# ADC_445 register map
Vendor: Texas Instruments
Peripheral module from a debugger description file (folder msp430).
Registers are 16-bit, read-write, no defined reset value unless marked. A register's access mark holds for its fields unless they carry their own. Offsets are as the file gives them; lines under a group give offsets from that group; [hi:lo] are bit positions; {n}, {i} and the like mark numbered series; 'fields as' and 'values as' point back to an identical list; <NAME> marks a mode.

## ADC
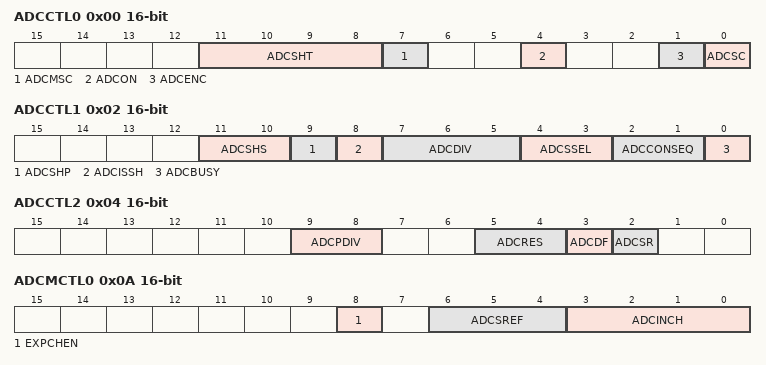
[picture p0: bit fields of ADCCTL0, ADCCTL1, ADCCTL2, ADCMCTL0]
0x00 ADCCTL0 — ADC Control 0
  [11:8] ADCSHT — sample-and-hold time.
    0=4 ADCCLK cycles; 1=8 ADCCLK cycles; 2=16 ADCCLK cycles; 3=32 ADCCLK cycles; 4=64 ADCCLK cycles; 5=96 ADCCLK cycles; 6=128 ADCCLK cycles; 7=192 ADCCLK cycles; 8=256 ADCCLK cycles; 9=384 ADCCLK cycles; 10=512 ADCCLK cycles; 11=768 ADCCLK cycles; {v}=1024 ADCCLK cycles (v=12..15)
  [7] ADCMSC — sample-and-hold time.
    0=The sampling timer requires a rising edge of the SHI signal to trigger each sample-and-convert; 1=The incidence of a positive(or for devices first rising edge of the) SHI signal triggers the sampling timer, but further sample-and-conversions are performed automatically as soon as the prior conversion is completed
  [4] ADCON
    0=ADC off; 1=ADC on
  [1] ADCENC — enable conversion
    0=ADC disabled; 1=ADC enabled
  [0] ADCSC — start conversion
    0=No sample-and-conversion-start; 1=Start sample-and-conversion
0x02 ADCCTL1 access per field — ADC Control 1
  [11:10] ADCSHS rw — sample-and-hold source select
    0=ADCSC bit; 1=see the device-specific data sheet for source; 2=see the device-specific data sheet for source; 3=see the device-specific data sheet for source
  [9] ADCSHP rw — sample-and-hold pulse-mode select
    0=SAMPCON signal is sourced from the sample-input signal; 1=SAMPCON signal is sourced from the sampling timer
  [8] ADCISSH rw — invert signal sample-and-hold
    0=The sample-input signal is not inverted; 1=The sample-input signal is inverted
  [7:5] ADCDIV rw — clock divider
    {v}=/{v+1} (v=0..7)
  [4:3] ADCSSEL rw — clock source select
    0=ADCOSC (MODOSC); 1=ACLK; 2=MCLK; 3=SMCLK
  [2:1] ADCCONSEQ rw — conversion sequence mode select
    0=Single-channel, single-conversion; 1=Sequence-of-channels; 2=Repeat-single-channel; 3=Repeat-sequence-of-channels
  [0] ADCBUSY ro
    0=No operation is active; 1=A sequence, sample, or conversion is active
0x04 ADCCTL2 — ADC Control 2
  [9:8] ADCPDIV — ADC predivider. This bit predivides the selected ADC clock source before it gets divided again using ADCDIVx.
    0=Predivide by 1; 1=Predivide by 4; 2=Predivide by 64
  [5:4] ADCRES — resolution
    0=8 bit; 1=10 bit; 2=12 bit
  [3] ADCDF — data read-back format
    0=Binary unsigned. Theoretically the analog input voltage V(REF) results in 0000h, the analog input voltage +V(REF) results in 03FFh.; 1=Signed binary (2s complement), left aligned. Theoretically the analog input voltage V(REF) results in 8000h, the analog input voltage +V(REF) results in 7FC0h.
  [2] ADCSR — ADC sampling rate.
0x06 ADCLO access not given — ADC Window Comparator Low Threshold Register
0x08 ADCHI access not given — ADC Window Comparator High Threshold Register
0x0A ADCMCTL0 — ADC Conversion Memory Control Register
  [8] EXPCHEN — ADC input channels expanded
    0=ADC channel expanded disable; 1=ADC channel expanded enable
  [6:4] ADCSREF — Select reference. It is not recommended to change this setting while a conversion is ongoing. Can be modified only when ADCENC = 0. Resetting ADCENC = 0 by software and changing these fields immediately shows an effect when a conversion is active.
    0=000b = V(R+) = AVCC and V(R-) = AVSS; 1=001b = V(R+) = VREF and V(R-) = AVSS; 2=010b = V(R+) = VEREF+ buffered and V(R-) = AVSS; 3=011b =V(R+) = VEREF+ and V(R-) = AVSS; 4=100b = V(R+) = AVCC and V(R-) = VEREF-; 5=101b = V(R+) = VREF and V(R-) = VEREF-; 6=110b = V(R+) = VEREF+ buffered and V(R-) = VEREF-; 7=111b = V(R+) = VEREF+ and V(R-) = VEREF-
  [3:0] ADCINCH — Input channel select
    {v}=A{v} - see device-specific data sheet (v=0..5); 6=A2 - see device-specific data sheet; {v}=A{v} - see device-specific data sheet (v=7..15)
0x12 ADCMEM0 access not given — ADC Conversion Memory Register
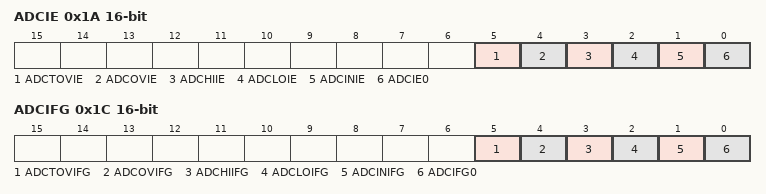
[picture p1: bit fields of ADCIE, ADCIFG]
0x1A ADCIE — ADC Interrupt Enable 0
  [5] ADCTOVIE — ADC conversion-time-overflow interrupt enable.
    0=0b = Conversion time overflow interrupt disabled; 1=1b = Conversion time overflow interrupt enabled
  [4] ADCOVIE — ADCMEM0 overflow interrupt enable.
    0=0b = Overflow interrupt disabled; 1=1b = Overflow interrupt enabled
  [3] ADCHIIE — Interrupt enable for the above upper threshold interrupt of the window comparator.
    0=0b = Above upper threshold interrupt disabled; 1=1b = Above upper threshold interrupt enabled
  [2] ADCLOIE — Interrupt enable for the below lower threshold interrupt of the window comparator.
    0=0b = Below lower threshold interrupt disabled; 1=1b = Below lower threshold interrupt enabled
  [1] ADCINIE — Interrupt enable for the inside of window interrupt of the window comparator.
    0=0b = Inside of window interrupt disabled; 1=1b = Inside of window interrupt enabled
  [0] ADCIE0 — Interrupt enable. This bits enable or disable the interrupt request for a completed ADC conversion.
    0=0b = Interrupt disabled; 1=1b = Interrupt enabled
0x1C ADCIFG — ADC Interrupt Flag
  [5] ADCTOVIFG — The ADCTOVIFG is set when an ADC conversion is triggered before the actual conversion has completed.
    0=ADCOVIFG_0 (No interrupt pending); 1=Interrupt pending
  [4] ADCOVIFG — The ADCOVIFG is set when the ADCMEM0 register is written before the last conversion result has been read.
    0=No interrupt pending; 1=Interrupt pending
  [3] ADCHIIFG — The ADCHIIFG is set when the result of the current ADC conversion is greater than the upper threshold defined by the window comparator upper threshold register.
    0=No interrupt pending; 1=Interrupt pending
  [2] ADCLOIFG — The ADCLOIFG is set when the result of the current ADC conversion is below the lower threshold defined by the window comparator lower threshold register.
    0=No interrupt pending; 1=Interrupt pending
  [1] ADCINIFG — The ADCINIFG is set when the result of the current ADC conversion is within the thresholds defined by the window comparator threshold registers.
    0=No interrupt pending; 1=Interrupt pending
  [0] ADCIFG0 — ADCMEM0 interrupt flag
    0=No interrupt pending; 1=Interrupt pending
0x1E ADCIV — ADC Interrupt Vector
  [15:0] ADCIV — interrupt vector value
    0=NONE (No interrupt pending); 2=ADCOVIFG (Interrupt Source: ADCMEM0 overflow; Interrupt Flag: ADCOVIFG; Interrupt Priority: Highest); 4=ADCTOVIFG (Interrupt Source: Conversion time overflow; Interrupt Flag: ADCTOVIFG); 6=ADCHIIFG (Interrupt Source: ADCHI Interrupt flag; Interrupt Flag: ADCHIIFG); 8=ADCLOIFG (Interrupt Source: ADCLO Interrupt flag; Interrupt Flag: ADCLOIFG); 10=ADCINIFG (nterrupt Source: ADCIN Interrupt flag; Interrupt Flag: ADCINIFG); 12=ADCIFG0 (Interrupt Source: ADC memory Interrupt flag; Interrupt Flag: ADCIFG0; Interrupt Priority: Lowest)
